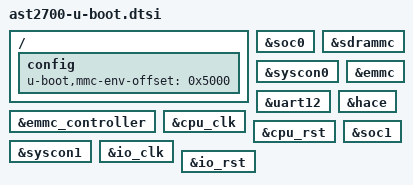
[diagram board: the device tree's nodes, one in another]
// SPDX-License-Identifier: GPL-2.0+

/ {
	config {
		u-boot,mmc-env-offset = <0x5000>;      /* @  20KB */
	};
};

&soc0 {
	bootph-all;
};

&sdrammc {
	bootph-all;
};

&syscon0 {
	bootph-all;
};

&uart12 {
	bootph-all;
};

&emmc_controller {
	bootph-all;
};

&emmc {
	bootph-all;
};

&hace {
	bootph-all;
};

&cpu_clk {
	bootph-all;
};

&cpu_rst {
	bootph-all;
};

&soc1 {
	bootph-all;
};

&syscon1 {
	bootph-all;
};

&io_clk {
	bootph-all;
};

&io_rst {
	bootph-all;
};
